# INTRCONN_SOCKET_PRM register map
Vendor: Texas Instruments
Peripheral module from a debugger description file (folder omap4430).
Registers are 32-bit, access per field, reset 0x0 unless marked. A register's access mark holds for its fields unless they carry their own. Offsets are as the file gives them; lines under a group give offsets from that group; [hi:lo] are bit positions; {n}, {i} and the like mark numbered series; 'fields as' and 'values as' point back to an identical list; <NAME> marks a mode.

## INTRCONN_SOCKET_PRM
0x00 REVISION_PRM ro reset not defined — This register contains the IP revision code for the PRM part of the PRCM
  [31:0] REV — Revision Number
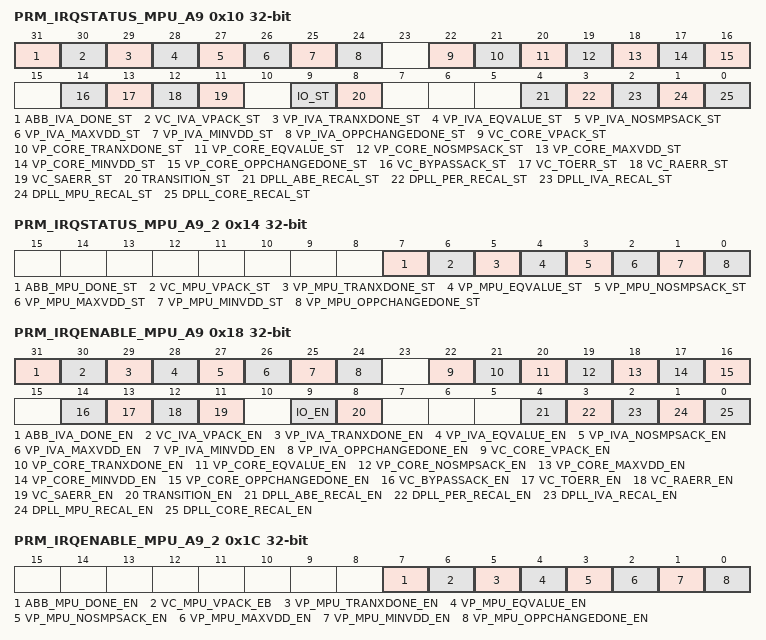
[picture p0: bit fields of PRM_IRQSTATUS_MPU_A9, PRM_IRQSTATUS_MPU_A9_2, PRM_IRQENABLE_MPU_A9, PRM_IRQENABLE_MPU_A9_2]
0x10 PRM_IRQSTATUS_MPU_A9 access not given — This register provides status on MPU interrupt events. Any event is logged independently of the corresponding IRQENABLE value. Software is required to clear a set bit by writing a 1 into the bit-position to be cleared.
  [all] fields
    0=No interrupt; 1=Interrupt is pending
  [31] ABB_IVA_DONE_ST — IVA ABB mode change done. This status is set when OPP_CHANGE bit is cleared by hardware in PRM_LDO_ABB_IVA_CRTL register. It is cleared by software. (access RW W1toClr)
  [30] VC_IVA_VPACK_ST — Voltage Controller IVA voltage processor command acknowledge status. (access RW W1toClr)
  [29] VP_IVA_TRANXDONE_ST — Voltage Processor IVA transaction completion status. This status is set when a transaction is completed in the voltage processor, including ABB mode change done if applicable (OPP_CHANGE bit cleared in PRM_LDO_ABB_IVA_CRTL). It is cleared by software. (access RW W1toClr)
  [28] VP_IVA_EQVALUE_ST — Voltage Processor IVA voltage value change event. This status is set when an update has been requested but the new voltage value is the same as the current SMPS voltage value. It is cleared by software. (access RW W1toClr)
  [27] VP_IVA_NOSMPSACK_ST — Voltage Processor IVA timeout event status. This status is set when the timeout occured before the SMPS acknowledge. It is cleared by software. (access RW W1toClr)
  [26] VP_IVA_MAXVDD_ST — Voltage Processor IVA voltage higher limit event status. This status is set when the voltage higher limit is reached. It is cleared by software. (access RW W1toClr)
  [25] VP_IVA_MINVDD_ST — Voltage Processor IVA voltage lower limit event status. This status is set when the voltage lower limit is reached. It is cleared by software. (access RW W1toClr)
  [24] VP_IVA_OPPCHANGEDONE_ST — Voltage Processor IVA OPP change done status, including ABB mode change done if applicable (OPP_CHANGE bit cleared in PRM_LDO_ABB_IVA_CRTL). It is cleared by software. (access RW W1toClr)
  [22] VC_CORE_VPACK_ST — Voltage Controller CORE voltage processor command acknowledge status (access RW W1toClr)
  [21] VP_CORE_TRANXDONE_ST — Voltage Processor CORE transaction completion status. This status is set when a transaction is completed in the voltage processor. It is cleared by software. (access RW W1toClr)
  [20] VP_CORE_EQVALUE_ST — Voltage Processor CORE voltage value change event. This status is set when an update has been requested but the new voltage value is the same as the current SMPS voltage value. It is cleared by software. (access RW W1toClr)
  [19] VP_CORE_NOSMPSACK_ST — Voltage Processor CORE timeout event status. This status is set when the timeout occured before the SMPS acknowledge. It is cleared by software. (access RW W1toClr)
  [18] VP_CORE_MAXVDD_ST — Voltage Processor CORE voltage higher limit event status. This status is set when the voltage higher limit is reached. It is cleared by software. (access RW W1toClr)
  [17] VP_CORE_MINVDD_ST — Voltage Processor CORE voltage lower limit event status. This status is set when the voltage lower limit is reached. It is cleared by software. (access RW W1toClr)
  [16] VP_CORE_OPPCHANGEDONE_ST — Voltage Processor CORE OPP change done status. It is cleared by software. (access RW W1toClr)
  [14] VC_BYPASSACK_ST — Voltage Controller bypass command acknowledge status. (access RW W1toClr)
  [13] VC_TOERR_ST — Voltage Controller timeout error event status. (access RW W1toClr)
  [12] VC_RAERR_ST — Voltage Controller register address acknowledge error event status. (access RW W1toClr)
  [11] VC_SAERR_ST — Voltage Controller slave address acknowledge error event status. (access RW W1toClr)
  [9] IO_ST — I/O pad event interrupt status. (access RW W1toClr)
  [8] TRANSITION_ST — Software supervised transition completed event interrupt status (any domain). Asserted upon completion of any clock domain force wakeup transition or upon completion of any power domain sleep transition with at least one enclosed clock domain configured in forced-sleep. (access RW W1toClr)
  [4] DPLL_ABE_RECAL_ST — ABE DPLL recalibration interrupt status. (access RW W1toClr)
  [3] DPLL_PER_RECAL_ST — PER DPLL recalibration interrupt status. (access RW W1toClr)
  [2] DPLL_IVA_RECAL_ST — IVA DPLL recalibration interrupt status. (access RW W1toClr)
  [1] DPLL_MPU_RECAL_ST — MPU DPLL recalibration interrupt status. (access RW W1toClr)
  [0] DPLL_CORE_RECAL_ST — CORE DPLL recalibration interrupt status. (access RW W1toClr)
0x14 PRM_IRQSTATUS_MPU_A9_2 access not given — This register provides status on MPU interrupt events. Any event is logged independently of the corresponding IRQENABLE value. Software is required to clear a set bit by writing a 1 into the bit-position to be cleared.
  [all] fields
    0=No interrupt; 1=Interrupt is pending
  [7] ABB_MPU_DONE_ST — MPU ABB mode change done. This status is set when OPP_CHANGE bit is cleared by hardware in PRM_LDO_ABB_MPU_CRTL register. It is cleared by software. (access RW W1toClr)
  [6] VC_MPU_VPACK_ST — Voltage Controller MPU voltage processor command acknowledge status. (access RW W1toClr)
  [5] VP_MPU_TRANXDONE_ST — Voltage Processor MPU transaction completion status. This status is set when a transaction is completed in the voltage processor, including ABB mode change done if applicable (OPP_CHANGE bit cleared in PRM_LDO_ABB_MPU_CRTL). It is cleared by software. (access RW W1toClr)
  [4] VP_MPU_EQVALUE_ST — Voltage Processor MPU voltage value change event. This status is set when an update has been requested but the new voltage value is the same as the current SMPS voltage value. It is cleared by software. (access RW W1toClr)
  [3] VP_MPU_NOSMPSACK_ST — Voltage Processor MPU timeout event status. This status is set when the timeout occured before the SMPS acknowledge. It is cleared by software. (access RW W1toClr)
  [2] VP_MPU_MAXVDD_ST — Voltage Processor MPU voltage higher limit event status. This status is set when the voltage higher limit is reached. It is cleared by software. (access RW W1toClr)
  [1] VP_MPU_MINVDD_ST — Voltage Processor MPU voltage lower limit event status. This status is set when the voltage lower limit is reached. It is cleared by software. (access RW W1toClr)
  [0] VP_MPU_OPPCHANGEDONE_ST — Voltage Processor MPU OPP change done status, including ABB mode change done if applicable (OPP_CHANGE bit cleared in PRM_LDO_ABB_MPU_CRTL). It is cleared by software. (access RW W1toClr)
0x18 PRM_IRQENABLE_MPU_A9 — This register is used to enable or disable MPU interrupt activation upon presence of corresponding bit.
  [all] fields
    0=Interrupt is masked; 1=Interrupt is enabled
  [31] ABB_IVA_DONE_EN rw — IIVA ABB mode change done enable.
  [30] VC_IVA_VPACK_EN rw — Voltage Controller IVA voltage processor command acknowledge enable.
  [29] VP_IVA_TRANXDONE_EN rw — Voltage Processor IVA transaction completion enable.
  [28] VP_IVA_EQVALUE_EN rw — Voltage Processor IVA voltage value change event enable.
  [27] VP_IVA_NOSMPSACK_EN rw — Voltage Processor IVA timeout event enable.
  [26] VP_IVA_MAXVDD_EN rw — Voltage Processor IVA voltage higher limit event enable.
  [25] VP_IVA_MINVDD_EN rw — Voltage Processor IVA voltage lower limit event enable.
  [24] VP_IVA_OPPCHANGEDONE_EN rw — Voltage Processor IVA OPP change done enable.
  [22] VC_CORE_VPACK_EN rw — Voltage Controller CORE voltage processor command acknowledge enable
  [21] VP_CORE_TRANXDONE_EN rw — Voltage Processor CORE transaction completion enable.
  [20] VP_CORE_EQVALUE_EN rw — Voltage Processor CORE voltage value change event enable.
  [19] VP_CORE_NOSMPSACK_EN rw — Voltage Processor CORE timeout event enable.
  [18] VP_CORE_MAXVDD_EN rw — Voltage Processor CORE voltage higher limit event enable.
  [17] VP_CORE_MINVDD_EN rw — Voltage Processor CORE voltage lower limit event enable.
  [16] VP_CORE_OPPCHANGEDONE_EN rw — Voltage Processor CORE OPP change done enable.
  [14] VC_BYPASSACK_EN rw — Voltage Controller bypass command acknowledge enable.
  [13] VC_TOERR_EN rw — Voltage Controller timeout error event enable.
  [12] VC_RAERR_EN rw — Voltage Controller register address acknowledge error event enable.
  [11] VC_SAERR_EN rw — Voltage Controller slave address acknowledge error event enable.
  [9] IO_EN rw — I/O pad event interrupt enable.
  [8] TRANSITION_EN rw — Software supervised transition completed event interrupt enable (any domain).
  [4] DPLL_ABE_RECAL_EN rw — ABE DPLL recalibration interrupt enable.
  [3] DPLL_PER_RECAL_EN rw — PER DPLL recalibration interrupt enable.
  [2] DPLL_IVA_RECAL_EN rw — IVA DPLL recalibration interrupt enable.
  [1] DPLL_MPU_RECAL_EN rw — MPU DPLL recalibration interrupt enable.
  [0] DPLL_CORE_RECAL_EN rw — CORE DPLL recalibration interrupt enable.
0x1C PRM_IRQENABLE_MPU_A9_2 — This register is used to enable or disable MPU interrupt activation upon presence of corresponding bit.
  [all] fields
    0=Interrupt is masked; 1=Interrupt is enabled
  [7] ABB_MPU_DONE_EN rw — MPU ABB mode change done enable.
  [6] VC_MPU_VPACK_EB rw — Voltage Controller MPU voltage processor command acknowledge enable.
  [5] VP_MPU_TRANXDONE_EN rw — Voltage Processor MPU transaction completion enable
  [4] VP_MPU_EQVALUE_EN rw — Voltage Processor MPU voltage value change event enable
  [3] VP_MPU_NOSMPSACK_EN rw — Voltage Processor MPU timeout event enable
  [2] VP_MPU_MAXVDD_EN rw — Voltage Processor MPU voltage higher limit event enable
  [1] VP_MPU_MINVDD_EN rw — Voltage Processor MPU voltage lower limit event enable
  [0] VP_MPU_OPPCHANGEDONE_EN rw — Voltage Processor MPU OPP change done enable
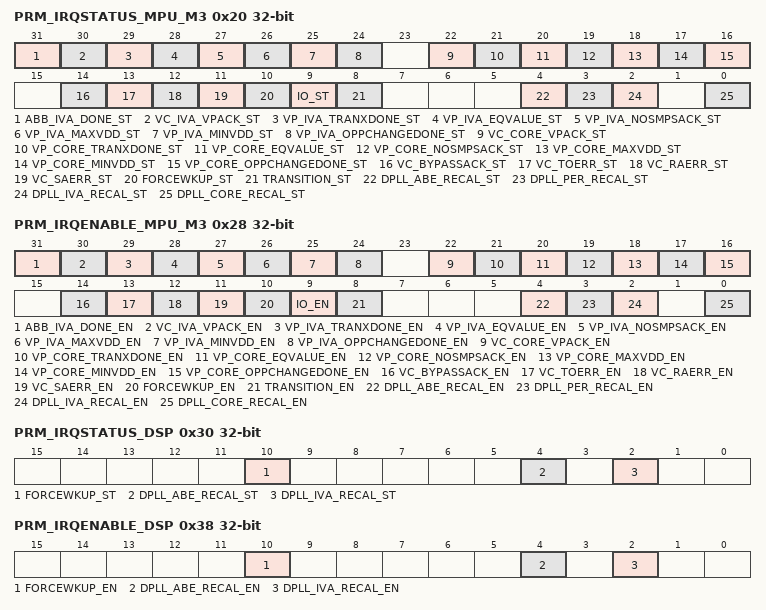
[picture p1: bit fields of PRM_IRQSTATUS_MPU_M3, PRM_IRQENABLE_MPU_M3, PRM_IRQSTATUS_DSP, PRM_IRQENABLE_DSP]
0x20 PRM_IRQSTATUS_MPU_M3 access not given — This register provides status on MPU_A3 interrupt events. Any event is logged independently of the corresponding IRQENABLE value. Software is required to clear a set bit by writing a 1 into the bit-position to be cleared.
  [all] fields
    0=No interrupt; 1=Interrupt is pending
  [31] ABB_IVA_DONE_ST — IVA ABB mode change done. This status is set when OPP_CHANGE bit is cleared by hardware in PRM_LDO_ABB_IVA_CRTL register. It is cleared by software. (access RW W1toClr)
  [30] VC_IVA_VPACK_ST — Voltage Controller IVA voltage processor command acknowledge status (access RW W1toClr)
  [29] VP_IVA_TRANXDONE_ST — Voltage Processor IVA transaction completion status. This status is set when a transaction is completed in the voltage processor, including ABB mode change done if applicable (OPP_CHANGE bit cleared in PRM_LDO_ABB_IVA_CRTL). It is cleared by software. (access RW W1toClr)
  [28] VP_IVA_EQVALUE_ST — Voltage Processor IVA voltage value change event. This status is set when an update has been requested but the new voltage value is the same as the current SMPS voltage value. It is cleared by software. (access RW W1toClr)
  [27] VP_IVA_NOSMPSACK_ST — Voltage Processor IVA timeout event status. This status is set when the timeout occured before the SMPS acknowledge. It is cleared by software. (access RW W1toClr)
  [26] VP_IVA_MAXVDD_ST — Voltage Processor IVA voltage higher limit event status. This status is set when the voltage higher limit is reached. It is cleared by software. (access RW W1toClr)
  [25] VP_IVA_MINVDD_ST — Voltage Processor IVA voltage lower limit event status. This status is set when the voltage lower limit is reached. It is cleared by software. (access RW W1toClr)
  [24] VP_IVA_OPPCHANGEDONE_ST — Voltage Processor IVA OPP change done status, including ABB mode change done if applicable (OPP_CHANGE bit cleared in PRM_LDO_ABB_IVA_CRTL). It is cleared by software. (access RW W1toClr)
  [22] VC_CORE_VPACK_ST — Voltage Controller CORE voltage processor command acknowledge status (access RW W1toClr)
  [21] VP_CORE_TRANXDONE_ST — Voltage Processor CORE transaction completion status. This status is set when a transaction is completed in the voltage processor. It is cleared by software. (access RW W1toClr)
  [20] VP_CORE_EQVALUE_ST — Voltage Processor CORE voltage value change event. This status is set when an update has been requested but the new voltage value is the same as the current SMPS voltage value. It is cleared by software. (access RW W1toClr)
  [19] VP_CORE_NOSMPSACK_ST — Voltage Processor CORE timeout event status. This status is set when the timeout occured before the SMPS acknowledge. It is cleared by software. (access RW W1toClr)
  [18] VP_CORE_MAXVDD_ST — Voltage Processor CORE voltage higher limit event status. This status is set when the voltage higher limit is reached. It is cleared by software. (access RW W1toClr)
  [17] VP_CORE_MINVDD_ST — Voltage Processor CORE voltage lower limit event status. This status is set when the voltage lower limit is reached. It is cleared by software. (access RW W1toClr)
  [16] VP_CORE_OPPCHANGEDONE_ST — Voltage Processor CORE OPP change done status. It is cleared by software. (access RW W1toClr)
  [14] VC_BYPASSACK_ST — Voltage Controller bypass command acknowledge status (access RW W1toClr)
  [13] VC_TOERR_ST — Voltage Controller timeout error event status (access RW W1toClr)
  [12] VC_RAERR_ST — Voltage Controller register address acknowledge error event status (access RW W1toClr)
  [11] VC_SAERR_ST — Voltage Controller slave address acknowledge error event status (access RW W1toClr)
  [10] FORCEWKUP_ST — CORTEXM3 domain software supervised wakeup transition completed event interrupt status. (access RW W1toClr)
  [9] IO_ST — I/O pad event interrupt status. (access RW W1toClr)
  [8] TRANSITION_ST — Software supervised transition completed event interrupt status (any domain). Asserted upon completion of any clock domain force wakeup transition or upon completion of any power domain sleep transition with at least one enclosed clock domain configured in forced-sleep. (access RW W1toClr)
  [4] DPLL_ABE_RECAL_ST — ABE DPLL recalibration interrupt status. (access RW W1toClr)
  [3] DPLL_PER_RECAL_ST — PER DPLL recalibration interrupt status. (access RW W1toClr)
  [2] DPLL_IVA_RECAL_ST — IVA DPLL recalibration interrupt status. (access RW W1toClr)
  [0] DPLL_CORE_RECAL_ST — CORE DPLL recalibration interrupt status. (access RW W1toClr)
0x28 PRM_IRQENABLE_MPU_M3 — This register is used to enable or disable MPU_A3 interrupt activation upon presence of corresponding bit.
  [all] fields
    0=Interrupt is masked; 1=Interrupt is enabled
  [31] ABB_IVA_DONE_EN rw — IVA ABB mode change done enable
  [30] VC_IVA_VPACK_EN rw — Voltage Controller IVA voltage processor command acknowledge enable
  [29] VP_IVA_TRANXDONE_EN rw — Voltage Processor IVA transaction completion enable
  [28] VP_IVA_EQVALUE_EN rw — Voltage Processor IVA voltage value change event enable
  [27] VP_IVA_NOSMPSACK_EN rw — Voltage Processor IVA timeout event enable
  [26] VP_IVA_MAXVDD_EN rw — Voltage Processor IVA voltage higher limit event enable
  [25] VP_IVA_MINVDD_EN rw — Voltage Processor IVA voltage lower limit event enable
  [24] VP_IVA_OPPCHANGEDONE_EN rw — Voltage Processor IVA OPP change done enable
  [22] VC_CORE_VPACK_EN rw — Voltage Controller CORE voltage processor command acknowledge enable
  [21] VP_CORE_TRANXDONE_EN rw — Voltage Processor CORE transaction completion enable
  [20] VP_CORE_EQVALUE_EN rw — Voltage Processor CORE voltage value change event enable
  [19] VP_CORE_NOSMPSACK_EN rw — Voltage Processor CORE timeout event enable
  [18] VP_CORE_MAXVDD_EN rw — Voltage Processor CORE voltage higher limit event enable
  [17] VP_CORE_MINVDD_EN rw — Voltage Processor CORE voltage lower limit event enable
  [16] VP_CORE_OPPCHANGEDONE_EN rw — Voltage Processor CORE OPP change done enable
  [14] VC_BYPASSACK_EN rw — Voltage Controller bypass command acknowledge enable
  [13] VC_TOERR_EN rw — Voltage Controller timeout error event enable
  [12] VC_RAERR_EN rw — Voltage Controller register address acknowledge error event enable
  [11] VC_SAERR_EN rw — Voltage Controller slave address acknowledge error event enable
  [10] FORCEWKUP_EN rw — CORTEXM3 domain software supervised wakeup transition completed event interrupt enable.
  [9] IO_EN rw — I/O pad event interrupt enable
  [8] TRANSITION_EN rw — Software supervised transition completed event interrupt enable (any domain)
  [4] DPLL_ABE_RECAL_EN rw — ABEDPLL recalibration interrupt enable
  [3] DPLL_PER_RECAL_EN rw — PER DPLL recalibration interrupt enable
  [2] DPLL_IVA_RECAL_EN rw — IVA DPLL recalibration interrupt enable
  [0] DPLL_CORE_RECAL_EN rw — CORE DPLL recalibration interrupt enable
0x30 PRM_IRQSTATUS_DSP access not given — This register provides status on DSP interrupt events. Any event is logged independently of the corresponding IRQENABLE value. Software is required to clear a set bit by writing a 1 into the bit-position to be cleared.
  [all] fields
    0=No interrupt; 1=Interrupt is pending
  [10] FORCEWKUP_ST — DSP domain software supervised wakeup transition completed event interrupt status. (access RW W1toClr)
  [4] DPLL_ABE_RECAL_ST — ABE DPLL recalibration interrupt status. (access RW W1toClr)
  [2] DPLL_IVA_RECAL_ST — IVA DPLL recalibration interrupt status. (access RW W1toClr)
0x38 PRM_IRQENABLE_DSP — This register is used to enable or disable DSP interrupt activation upon presence of corresponding bit.
  [all] fields
    0=Interrupt is masked; 1=Interrupt is enabled
  [10] FORCEWKUP_EN rw — DSP domain software supervised wakeup transition completed event interrupt enable.
  [4] DPLL_ABE_RECAL_EN rw — ABEDPLL recalibration interrupt enable
  [2] DPLL_IVA_RECAL_EN rw — IVA DPLL recalibration interrupt enable
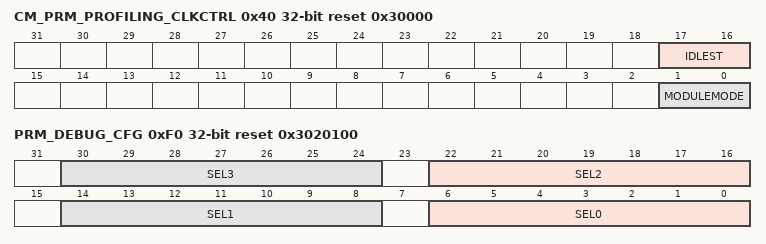
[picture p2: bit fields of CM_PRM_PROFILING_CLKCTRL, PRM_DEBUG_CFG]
0x40 CM_PRM_PROFILING_CLKCTRL reset 0x30000 — This register manages the PRM_PROFILING clock. [warm reset insensitive]
  [17:16] IDLEST ro — Module idle status
    0=IDLEST_0_r (Module is fully functional); 1=IDLEST_1_r (Module is performing transition: wakeup, or sleep, or sleep abortion); 2=IDLEST_2_r (Module is in Idle); 3=IDLEST_3_r (Module is disabled)
  [1:0] MODULEMODE rw — Control the way mandatory clocks are managed.
    0=Module is disabled by software. INTRCONN configuration port is not accessible.; 1=Module is managed automatically by hardware along with EMU domain. INTRCONN configuration port is accessible only when EMU domain is on.; 2=MODULEMODE_2_r (Reserved); 3=MODULEMODE_3_r (Reserved)
0xF0 PRM_DEBUG_CFG reset 0x3020100 — This register is used to configure the PRM's 32-bit debug output. There is one 7-bit source select field for selecting from a shared set of 8-bit internal signal blocks per byte. [warm reset insensitive]
  [8n+6:8n] SEL{n} rw (n=0..3) — Internal signal block select for debug word byte-{n}
